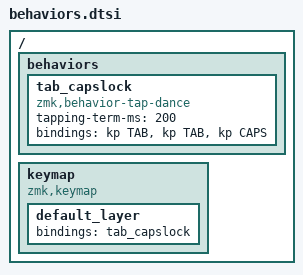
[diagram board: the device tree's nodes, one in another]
// Map CAPS to triple tap LSHIFT
/ {
    behaviors {
        tab_capslock: tab_capslock {
            compatible = "zmk,behavior-tap-dance";
            #binding-cells = <0>;
            tapping-term-ms = <200>;
            bindings = <&kp TAB>, <&kp TAB>, <&kp CAPS>;
        };
    };

    keymap {
        compatible = "zmk,keymap";

        default_layer {
            bindings = <
                &tab_capslock
            >;
        };
    };
};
